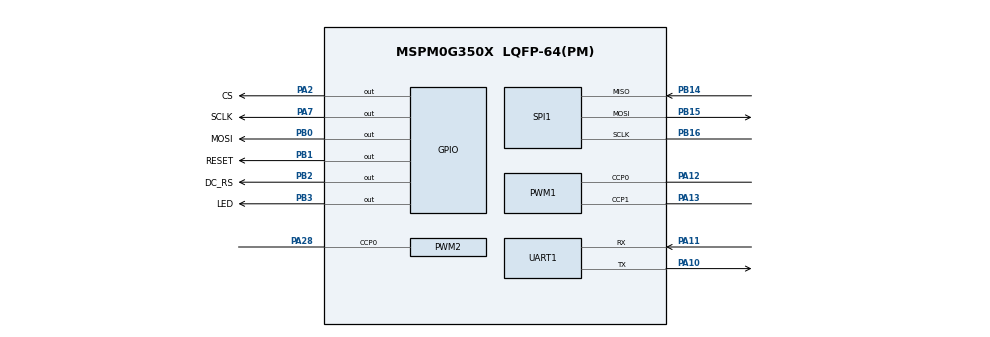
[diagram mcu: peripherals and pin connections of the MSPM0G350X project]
/**
 * These arguments were used when this file was generated. They will be automatically applied on subsequent loads
 * via the GUI or CLI. Run CLI with '--help' for additional information on how to override these arguments.
 * @cliArgs --device "MSPM0G350X" --package "LQFP-64(PM)" --part "Default" --product "mspm0_sdk@2.01.00.03"
 * @versions {"tool":"1.19.0+3426"}
 */

/**
 * Import the modules used in this configuration.
 */
const GPIO          = scripting.addModule("/ti/driverlib/GPIO", {}, false);
const GPIO1         = GPIO.addInstance();
const GPIO2         = GPIO.addInstance();
const GPIO3         = GPIO.addInstance();
const GPIO4         = GPIO.addInstance();
const PWM           = scripting.addModule("/ti/driverlib/PWM", {}, false);
const PWM1          = PWM.addInstance();
const PWM2          = PWM.addInstance();
const SPI           = scripting.addModule("/ti/driverlib/SPI", {}, false);
const SPI1          = SPI.addInstance();
const SYSCTL        = scripting.addModule("/ti/driverlib/SYSCTL");
const TIMER         = scripting.addModule("/ti/driverlib/TIMER", {}, false);
const TIMER1        = TIMER.addInstance();
const UART          = scripting.addModule("/ti/driverlib/UART", {}, false);
const UART1         = UART.addInstance();
const ProjectConfig = scripting.addModule("/ti/project_config/ProjectConfig");

/**
 * Write custom configuration values to the imported modules.
 */
const divider7       = system.clockTree["PLL_PDIV"];
divider7.divideValue = 4;

const divider9       = system.clockTree["UDIV"];
divider9.divideValue = 2;

const gate7  = system.clockTree["MFCLKGATE"];
gate7.enable = true;

const gate8  = system.clockTree["MFPCLKGATE"];
gate8.enable = true;

const multiplier2         = system.clockTree["PLL_QDIV"];
multiplier2.multiplyValue = 9;

const mux8       = system.clockTree["HSCLKMUX"];
mux8.inputSelect = "HSCLKMUX_SYSPLL2X";

GPIO1.port                                = "PORTA";
GPIO1.$name                               = "GPIO_A";
GPIO1.associatedPins[0].launchPadShortcut = "LED1En";
GPIO1.associatedPins[0].ioStructure       = "OD";
GPIO1.associatedPins[0].$name             = "LED1";

const Board = scripting.addModule("/ti/driverlib/Board", {}, false);

GPIO2.$name                         = "ENCODER_A";
GPIO2.port                          = "PORTA";
GPIO2.associatedPins.create(2);
GPIO2.associatedPins[0].$name       = "E1A";
GPIO2.associatedPins[0].direction   = "INPUT";
GPIO2.associatedPins[0].assignedPin = "16";
GPIO2.associatedPins[0].interruptEn = true;
GPIO2.associatedPins[0].polarity    = "RISE";
GPIO2.associatedPins[1].$name       = "E1B";
GPIO2.associatedPins[1].direction   = "INPUT";
GPIO2.associatedPins[1].assignedPin = "15";
GPIO2.associatedPins[1].interruptEn = true;
GPIO2.associatedPins[1].polarity    = "RISE";

GPIO3.$name                         = "ENCODER_B";
GPIO3.port                          = "PORTA";
GPIO3.associatedPins.create(2);
GPIO3.associatedPins[0].$name       = "E2A";
GPIO3.associatedPins[0].direction   = "INPUT";
GPIO3.associatedPins[0].assignedPin = "17";
GPIO3.associatedPins[0].interruptEn = true;
GPIO3.associatedPins[0].polarity    = "RISE";
GPIO3.associatedPins[1].$name       = "E2B";
GPIO3.associatedPins[1].direction   = "INPUT";
GPIO3.associatedPins[1].assignedPin = "22";
GPIO3.associatedPins[1].interruptEn = true;
GPIO3.associatedPins[1].polarity    = "RISE";

GPIO4.$name                              = "TFT";
GPIO4.associatedPins.create(6);
GPIO4.associatedPins[0].$name            = "CS";
GPIO4.associatedPins[0].assignedPort     = "PORTA";
GPIO4.associatedPins[0].assignedPin      = "2";
GPIO4.associatedPins[0].internalResistor = "PULL_UP";
GPIO4.associatedPins[0].pin.$assign      = "PA2";
GPIO4.associatedPins[1].$name            = "RESET";
GPIO4.associatedPins[1].assignedPort     = "PORTB";
GPIO4.associatedPins[1].assignedPin      = "1";
GPIO4.associatedPins[1].internalResistor = "PULL_UP";
GPIO4.associatedPins[1].pin.$assign      = "PB1";
GPIO4.associatedPins[2].$name            = "DC_RS";
GPIO4.associatedPins[2].internalResistor = "PULL_UP";
GPIO4.associatedPins[2].assignedPort     = "PORTB";
GPIO4.associatedPins[2].assignedPin      = "2";
GPIO4.associatedPins[2].pin.$assign      = "PB2";
GPIO4.associatedPins[3].$name            = "MOSI";
GPIO4.associatedPins[3].internalResistor = "PULL_UP";
GPIO4.associatedPins[3].assignedPort     = "PORTB";
GPIO4.associatedPins[3].assignedPin      = "0";
GPIO4.associatedPins[3].pin.$assign      = "PB0";
GPIO4.associatedPins[4].$name            = "SCLK";
GPIO4.associatedPins[4].internalResistor = "PULL_UP";
GPIO4.associatedPins[4].assignedPort     = "PORTA";
GPIO4.associatedPins[4].assignedPin      = "7";
GPIO4.associatedPins[4].pin.$assign      = "PA7";
GPIO4.associatedPins[5].$name            = "LED";
GPIO4.associatedPins[5].initialValue     = "SET";
GPIO4.associatedPins[5].assignedPort     = "PORTB";
GPIO4.associatedPins[5].assignedPin      = "3";
GPIO4.associatedPins[5].pin.$assign      = "PB3";

PWM1.$name                              = "PWM_MOTOR";
PWM1.pwmMode                            = "EDGE_ALIGN_UP";
PWM1.clockPrescale                      = 36;
PWM1.peripheral.$assign                 = "TIMG0";
PWM1.peripheral.ccp0Pin.$assign         = "PA12";
PWM1.peripheral.ccp1Pin.$assign         = "PA13";
PWM1.PWM_CHANNEL_0.$name                = "ti_driverlib_pwm_PWMTimerCC0";
PWM1.PWM_CHANNEL_0.ccValue              = 1000;
PWM1.PWM_CHANNEL_1.$name                = "ti_driverlib_pwm_PWMTimerCC1";
PWM1.PWM_CHANNEL_1.ccValue              = 1000;
PWM1.ccp0PinConfig.direction            = scripting.forceWrite("OUTPUT");
PWM1.ccp0PinConfig.hideOutputInversion  = scripting.forceWrite(false);
PWM1.ccp0PinConfig.onlyInternalResistor = scripting.forceWrite(false);
PWM1.ccp0PinConfig.passedPeripheralType = scripting.forceWrite("Digital");
PWM1.ccp0PinConfig.$name                = "ti_driverlib_gpio_GPIOPinGeneric2";
PWM1.ccp1PinConfig.direction            = scripting.forceWrite("OUTPUT");
PWM1.ccp1PinConfig.hideOutputInversion  = scripting.forceWrite(false);
PWM1.ccp1PinConfig.onlyInternalResistor = scripting.forceWrite(false);
PWM1.ccp1PinConfig.passedPeripheralType = scripting.forceWrite("Digital");
PWM1.ccp1PinConfig.$name                = "ti_driverlib_gpio_GPIOPinGeneric3";

PWM2.$name                              = "PWM_SERVO";
PWM2.clockPrescale                      = 144;
PWM2.timerCount                         = 10000;
PWM2.pwmMode                            = "EDGE_ALIGN_UP";
PWM2.ccIndex                            = [0];
PWM2.timerStartTimer                    = true;
PWM2.peripheral.$assign                 = "TIMA1";
PWM2.peripheral.ccp0Pin.$assign         = "PA28";
PWM2.PWM_CHANNEL_0.$name                = "ti_driverlib_pwm_PWMTimerCC2";
PWM2.PWM_CHANNEL_0.ccValue              = 1000;
PWM2.ccp0PinConfig.$name                = "ti_driverlib_gpio_GPIOPinGeneric7";
PWM2.ccp0PinConfig.direction            = scripting.forceWrite("OUTPUT");
PWM2.ccp0PinConfig.hideOutputInversion  = scripting.forceWrite(false);
PWM2.ccp0PinConfig.onlyInternalResistor = scripting.forceWrite(false);
PWM2.ccp0PinConfig.passedPeripheralType = scripting.forceWrite("Digital");

SPI1.frameFormat                        = "MOTO3";
SPI1.$name                              = "HARDSPI_TFT";
SPI1.targetBitRate                      = 30000000;
SPI1.peripheral.$assign                 = "SPI1";
SPI1.peripheral.sclkPin.$assign         = "PB16";
SPI1.peripheral.mosiPin.$assign         = "PB15";
SPI1.peripheral.misoPin.$assign         = "PB14";
SPI1.sclkPinConfig.direction            = scripting.forceWrite("OUTPUT");
SPI1.sclkPinConfig.onlyInternalResistor = scripting.forceWrite(false);
SPI1.sclkPinConfig.passedPeripheralType = scripting.forceWrite("Digital");
SPI1.sclkPinConfig.$name                = "ti_driverlib_gpio_GPIOPinGeneric4";
SPI1.sclkPinConfig.enableConfig         = true;
SPI1.sclkPinConfig.internalResistor     = "PULL_UP";
SPI1.mosiPinConfig.direction            = scripting.forceWrite("OUTPUT");
SPI1.mosiPinConfig.hideOutputInversion  = scripting.forceWrite(false);
SPI1.mosiPinConfig.onlyInternalResistor = scripting.forceWrite(false);
SPI1.mosiPinConfig.passedPeripheralType = scripting.forceWrite("Digital");
SPI1.mosiPinConfig.$name                = "ti_driverlib_gpio_GPIOPinGeneric5";
SPI1.misoPinConfig.onlyInternalResistor = scripting.forceWrite(false);
SPI1.misoPinConfig.passedPeripheralType = scripting.forceWrite("Digital");
SPI1.misoPinConfig.$name                = "ti_driverlib_gpio_GPIOPinGeneric6";
SPI1.misoPinConfig.enableConfig         = true;
SPI1.misoPinConfig.internalResistor     = "PULL_UP";

SYSCTL.clockTreeEn = true;

TIMER1.$name            = "TIMER_0";
TIMER1.interrupts       = ["ZERO"];
TIMER1.timerClkDiv      = 8;
TIMER1.timerMode        = "PERIODIC_UP";
TIMER1.timerStartTimer  = true;
TIMER1.timerPeriod      = "10 ms";
TIMER1.timerClkPrescale = 90;

UART1.$name                    = "UART_0";
UART1.enableFIFO               = true;
UART1.rxFifoThreshold          = "DL_UART_RX_FIFO_LEVEL_ONE_ENTRY";
UART1.enableInternalLoopback   = true;
UART1.enableDMARX              = false;
UART1.enableDMATX              = false;
UART1.peripheral.$assign       = "UART0";
UART1.peripheral.rxPin.$assign = "PA11";
UART1.peripheral.txPin.$assign = "PA10";
UART1.txPinConfig.$name        = "ti_driverlib_gpio_GPIOPinGeneric0";
UART1.rxPinConfig.$name        = "ti_driverlib_gpio_GPIOPinGeneric1";

ProjectConfig.deviceSpin = "MSPM0G3507";

/**
 * Pinmux solution for unlocked pins/peripherals. This ensures that minor changes to the automatic solver in a future
 * version of the tool will not impact the pinmux you originally saw.  These lines can be completely deleted in order to
 * re-solve from scratch.
 */
GPIO1.associatedPins[0].pin.$suggestSolution = "PA0";
Board.peripheral.$suggestSolution            = "DEBUGSS";
Board.peripheral.swclkPin.$suggestSolution   = "PA20";
Board.peripheral.swdioPin.$suggestSolution   = "PA19";
GPIO2.associatedPins[0].pin.$suggestSolution = "PA16";
GPIO2.associatedPins[1].pin.$suggestSolution = "PA15";
GPIO3.associatedPins[0].pin.$suggestSolution = "PA17";
GPIO3.associatedPins[1].pin.$suggestSolution = "PA22";
TIMER1.peripheral.$suggestSolution           = "TIMA0";
